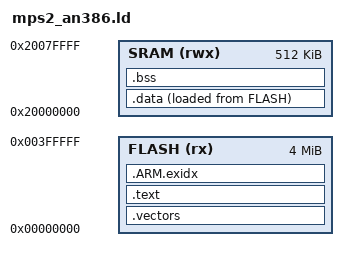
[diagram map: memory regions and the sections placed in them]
/* Linker script for MPS2-AN386 (Cortex-M4) */
MEMORY
{
    FLASH (rx)  : ORIGIN = 0x00000000, LENGTH = 4M
    SRAM  (rwx) : ORIGIN = 0x20000000, LENGTH = 512K
}

ENTRY(Reset_Handler)

SECTIONS
{
    .vectors : {
        KEEP(*(.vectors))
    } > FLASH

    .text : {
        *(.text*)
        *(.rodata*)
    } > FLASH

    .ARM.exidx : {
        *(.ARM.exidx*)
    } > FLASH

    .data : {
        _sdata = .;
        *(.data*)
        _edata = .;
    } > SRAM AT > FLASH

    .bss : {
        _sbss = .;
        *(.bss*)
        *(COMMON)
        _ebss = .;
    } > SRAM

    _estack = ORIGIN(SRAM) + LENGTH(SRAM);
}
